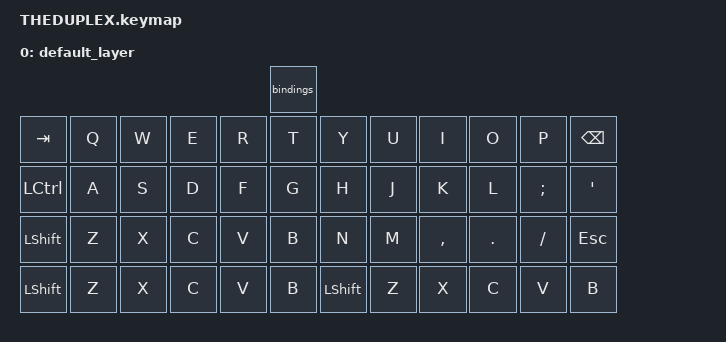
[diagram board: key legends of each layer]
#include <behaviors.dtsi>
#include <dt-bindings/zmk/keys.h>

/ {
    keymap {
        compatible = "zmk,keymap";

        default_layer { // Layer 0
            // -------------------------------------
            // |     Z     |     M     |     K     |
            // |     A     |     B     |     C     |
            // |     D     |     E     |     F     |
            bindings = <
                                        bindings = <
   &kp TAB   &kp Q &kp W &kp E &kp R &kp T   &kp Y &kp U  &kp I     &kp O   &kp P    &kp BSPC
   &kp LCTRL &kp A &kp S &kp D &kp F &kp G   &kp H &kp J  &kp K     &kp L   &kp SEMI &kp SQT
   &kp LSHFT &kp Z &kp X &kp C &kp V &kp B   &kp N &kp M  &kp COMMA &kp DOT &kp FSLH &kp ESC
   &kp LSHFT &kp Z &kp X &kp C &kp V &kp B   &kp LSHFT &kp Z &kp X &kp C &kp V &kp B
            >;
        };
    };
 };
